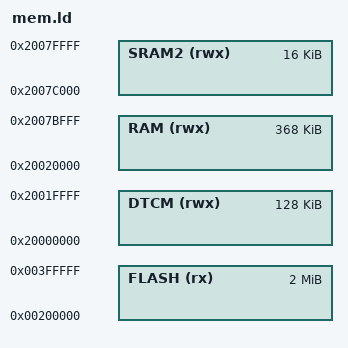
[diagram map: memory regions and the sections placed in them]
MEMORY {
	FLASH (rx)	: ORIGIN = 0x00200000, LENGTH = 0x200000	/* 2048K */
	RAM (rwx)	: ORIGIN = 0x20020000, LENGTH = 0x5C000		/* 368K  */
	DTCM  (rwx)	: ORIGIN = 0x20000000, LENGTH = 0x20000		/* 128K  */
	SRAM2 (rwx)	: ORIGIN = 0x2007C000, LENGTH = 0x4000		/* 16K   */
}
